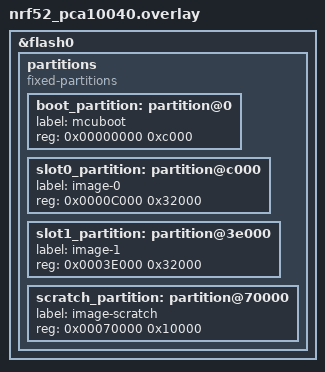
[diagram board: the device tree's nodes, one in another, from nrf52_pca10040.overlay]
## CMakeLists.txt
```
# SPDX-License-Identifier: Apache-2.0

cmake_minimum_required(VERSION 3.28.0)
find_package(Zephyr REQUIRED HINTS $ENV{ZEPHYR_BASE})
project(settings_fcb_raw)

add_subdirectory(./src fcb_test_bindir)

if(TEST)
  target_compile_definitions(app PRIVATE
    -DTEST_${TEST}
  )
endif()
```

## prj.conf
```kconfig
CONFIG_ZTEST=y
CONFIG_ZTEST_STACK_SIZE=2048

CONFIG_FLASH=y
CONFIG_FLASH_MAP=y
CONFIG_FCB=y

CONFIG_SETTINGS=y
CONFIG_SETTINGS_RUNTIME=y
CONFIG_SETTINGS_FCB=y
```

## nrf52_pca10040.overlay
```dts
&flash0 {
	/*
	 * For more information, see:
	 * http://docs.zephyrproject.org/latest/devices/dts/flash_partitions.html
	 */
	partitions {
		compatible = "fixed-partitions";
		#address-cells = <1>;
		#size-cells = <1>;

		boot_partition: partition@0 {
			label = "mcuboot";
			reg = <0x00000000 0xc000>;
		};
		slot0_partition: partition@c000 {
			label = "image-0";
			reg = <0x0000C000 0x32000>;
		};
		slot1_partition: partition@3e000 {
			label = "image-1";
			reg = <0x0003E000 0x32000>;
		};
		scratch_partition: partition@70000 {
			label = "image-scratch";
			reg = <0x00070000 0x10000>;
		};
	};
};
```

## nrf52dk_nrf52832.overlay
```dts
/*
 * Copyright (c) 2018 Nordic Semiconductor ASA
 *
 * SPDX-License-Identifier: Apache-2.0
 */

/delete-node/ &storage_partition;
/delete-node/ &scratch_partition;

&flash0 {

	partitions {
		compatible = "fixed-partitions";
		#address-cells = <1>;
		#size-cells = <1>;

		storage_partition: partition@70000 {
			label = "storage";
			reg = <0x00070000 0x10000>;
		};
	};
};
```

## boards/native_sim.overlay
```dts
/*
 * Copyright (c) 2019 Jan Van Winkel <jan.van_winkel@dxplore.eu>
 *
 * SPDX-License-Identifier: Apache-2.0
 */

/delete-node/ &storage_partition;
/delete-node/ &scratch_partition;

&flash0 {
	partitions {
		compatible = "fixed-partitions";
		#address-cells = <1>;
		#size-cells = <1>;

		storage_partition: partition@70000 {
			reg = <0x00070000 0x10000>;
			label = "storage";
		};
	};
};
```

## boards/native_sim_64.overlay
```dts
/*
 * Copyright (c) 2019 Jan Van Winkel <jan.van_winkel@dxplore.eu>
 *
 * SPDX-License-Identifier: Apache-2.0
 */

#include "native_sim.overlay"
```

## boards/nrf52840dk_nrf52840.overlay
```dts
/*
 * Copyright (c) 2019 Nordic Semiconductor ASA
 *
 * SPDX-License-Identifier: Apache-2.0
 */

/delete-node/ &storage_partition;

&flash0 {
	partitions {
		storage_partition: partition@de000 {
			compatible = "zephyr,mapped-partition";
			reg = <0x000de000 0x00010000>;
			label = "storage";
		};
	};
};
```

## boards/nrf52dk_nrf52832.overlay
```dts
/*
 * Copyright (c) 2018 Nordic Semiconductor ASA
 *
 * SPDX-License-Identifier: Apache-2.0
 */

/delete-node/ &storage_partition;
/delete-node/ &slot1_partition;

&flash0 {
	partitions {
		ranges;
		#address-cells = <1>;
		#size-cells = <1>;

		storage_partition: partition@70000 {
			compatible = "zephyr,mapped-partition";
			label = "storage";
			reg = <0x00070000 0x10000>;
		};
	};
};
```

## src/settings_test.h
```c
/*
 * Copyright (c) 2018 Nordic Semiconductor ASA
 * Copyright (c) 2015 Runtime Inc
 *
 * SPDX-License-Identifier: Apache-2.0
 */

#ifndef _SETTINGS_TEST_FCB_H
#define _SETTINGS_TEST_FCB_H

#include <stdio.h>
#include <string.h>
#include <zephyr/ztest.h>

#include <zephyr/settings/settings.h>
#include <zephyr/storage/flash_map.h>

#ifdef __cplusplus
extern "C" {
#endif

#define SETTINGS_TEST_FCB_VAL_STR_CNT   64
#define SETTINGS_TEST_FCB_FLASH_CNT   4


extern uint8_t val8;
extern uint8_t val8_un;
extern uint32_t val32;
extern uint64_t val64;

extern int test_get_called;
extern int test_set_called;
extern int test_commit_called;
extern int test_export_block;

extern int c2_var_count;

extern const struct flash_sector fcb_sectors[SETTINGS_TEST_FCB_FLASH_CNT];

extern char val_string[SETTINGS_TEST_FCB_VAL_STR_CNT][SETTINGS_MAX_VAL_LEN];
extern char test_ref_value[SETTINGS_TEST_FCB_VAL_STR_CNT][SETTINGS_MAX_VAL_LEN];

extern struct settings_handler c_test_handlers[];

void ctest_clear_call_state(void);
int ctest_get_call_state(void);

void config_wipe_srcs(void);
void config_wipe_fcb(const struct flash_sector *fs, int cnt);

void test_config_fill_area(
	char test_value[SETTINGS_TEST_FCB_VAL_STR_CNT][SETTINGS_MAX_VAL_LEN],
		int iteration);

void *settings_config_setup(void);
void settings_config_teardown(void *fixture);
void test_config_insert2(void);
void test_config_insert3(void);
int settings_unregister(struct settings_handler *handler);
#ifdef __cplusplus
}
#endif
#endif /* _SETTINGS_TEST_FCB_H */
```

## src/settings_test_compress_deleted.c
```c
/*
 * Copyright (c) 2018 Nordic Semiconductor ASA
 *
 * SPDX-License-Identifier: Apache-2.0
 */

#include "settings_test.h"
#include <settings/settings_fcb.h>

#define NAME_DELETABLE "4/deletable"

struct flash_sector fcb_small_sectors[2] = {
	[0] = {
		.fs_off = 0x00000000,
		.fs_size = 4 * 1024
	},
	[1] = {
		.fs_off = 0x00001000,
		.fs_size = 4 * 1024
	}
};

struct deletable_s {
	bool valid;
	uint32_t val32;
} deletable_val;

uint32_t val4v2;

int c4_handle_export(int (*cb)(const char *name, const void *value, size_t val_len));
int c4_handle_set(const char *name, size_t len, settings_read_cb read_cb,
		  void *cb_arg);

struct settings_handler c4_test_handler = {
	.name = "4",
	.h_get = NULL,
	.h_set = c4_handle_set,
	.h_commit = NULL,
	.h_export = c4_handle_export
};

int c4_handle_set(const char *name, size_t len, settings_read_cb read_cb,
		  void *cb_arg)
{
	return 0;
}

int c4_handle_export(int (*cb)(const char *name, const void *value, size_t val_len))
{
	if (deletable_val.valid) {
		(void)cb(NAME_DELETABLE, &deletable_val.val32,
			 sizeof(deletable_val.val32));
	} else {
		(void)cb(NAME_DELETABLE, NULL, 0);
	}

	(void)cb("4/dummy", &val4v2, sizeof(val4v2));

	return 0;
}

static int check_compressed_cb(struct fcb_entry_ctx *entry_ctx, void *arg)
{
	char buf[SETTINGS_MAX_NAME_LEN + SETTINGS_MAX_VAL_LEN +
		 SETTINGS_EXTRA_LEN];
	int rc;
	int len;

	len = entry_ctx->loc.fe_data_len;
	if (len >= sizeof(buf)) {
		len = sizeof(buf) - 1;
	}

	rc = flash_area_read(entry_ctx->fap,
			     FCB_ENTRY_FA_DATA_OFF(entry_ctx->loc), buf, len);

	if (rc) {
		return 0;
	}
	buf[len] = '\0';

	rc = strncmp(buf, NAME_DELETABLE, sizeof(NAME_DELETABLE)-1);
	zassert_true(rc != 0, "The deleted settings shouldn be compressed.");

	return 0;
}

ZTEST(settings_config_fcb, test_config_compress_deleted)
{
	int rc;
	struct settings_fcb cf;
	int i;

	config_wipe_srcs();
	config_wipe_fcb(fcb_small_sectors, ARRAY_SIZE(fcb_small_sectors));

	cf.cf_fcb.f_magic = CONFIG_SETTINGS_FCB_MAGIC;
	cf.cf_fcb.f_sectors = fcb_small_sectors;
	cf.cf_fcb.f_sector_cnt = ARRAY_SIZE(fcb_small_sectors);

	rc = settings_fcb_src(&cf);
	zassert_true(rc == 0, "can't register FCB as configuration source");
	settings_mount_fcb_backend(&cf);

	rc = settings_fcb_dst(&cf);
	zassert_true(rc == 0,
		     "can't register FCB as configuration destination");

	rc = settings_register(&c4_test_handler);
	zassert_true(rc == 0, "settings_register fail");

	deletable_val.valid = true;
	deletable_val.val32 = 2018U;
	val4v2 = 0U;

	rc = settings_save();
	zassert_true(rc == 0, "fcb write error");

	deletable_val.valid = false;

	for (i = 0; ; i++) {
		val4v2++;

		rc = settings_save();
		zassert_true(rc == 0, "fcb write error");

		if (cf.cf_fcb.f_active.fe_sector == &fcb_small_sectors[1]) {
			/*
			 * The compression should happened while the active
			 * sector was changing.
			 */
			break;
		}
	}

	rc = fcb_walk(&cf.cf_fcb, &fcb_small_sectors[1], check_compressed_cb,
		      NULL);
	settings_unregister(&c4_test_handler);
}
```

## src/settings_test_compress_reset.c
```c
/*
 * Copyright (c) 2018 Nordic Semiconductor ASA
 * Copyright (c) 2015 Runtime Inc
 *
 * SPDX-License-Identifier: Apache-2.0
 */

#include "settings_test.h"
#include <settings/settings_fcb.h>

ZTEST(settings_config_fcb, test_config_compress_reset)
{
	int rc;
	struct settings_fcb cf;
	struct flash_sector *fa;
	int elems[4];
	int i;

	rc = settings_register(&c_test_handlers[1]);
	zassert_true(rc == 0 || rc == -EEXIST, "settings_register fail");
	config_wipe_srcs();
	config_wipe_fcb(fcb_sectors, ARRAY_SIZE(fcb_sectors));

	cf.cf_fcb.f_magic = CONFIG_SETTINGS_FCB_MAGIC;
	cf.cf_fcb.f_sectors = fcb_sectors;
	cf.cf_fcb.f_sector_cnt = ARRAY_SIZE(fcb_sectors);

	rc = settings_fcb_src(&cf);
	zassert_true(rc == 0, "can't register FCB as configuration source");
	settings_mount_fcb_backend(&cf);

	rc = settings_fcb_dst(&cf);
	zassert_true(rc == 0,
		     "can't register FCB as configuration destination");

	c2_var_count = 1;
	(void)memset(elems, 0, sizeof(elems));

	for (i = 0; ; i++) {
		test_config_fill_area(test_ref_value, i);
		memcpy(val_string, test_ref_value, sizeof(val_string));

		rc = settings_save();
		zassert_true(rc == 0, "fcb write error");

		if (cf.cf_fcb.f_active.fe_sector == &fcb_sectors[2]) {
			/*
			 * Started using space just before scratch.
			 */
			break;
		}
		(void)memset(val_string, 0, sizeof(val_string));

		rc = settings_load();
		zassert_true(rc == 0, "fcb read error");
		zassert_true(!memcmp(val_string, test_ref_value,
				     SETTINGS_MAX_VAL_LEN),
			     "bad value read");
	}

	fa = cf.cf_fcb.f_active.fe_sector;
	rc = fcb_append_to_scratch(&cf.cf_fcb);
	zassert_true(rc == 0, "fcb_append_to_scratch call failure");
	zassert_true(fcb_free_sector_cnt(&cf.cf_fcb) == 0,
		     "expected non of free sectors");
	zassert_true(fa != cf.cf_fcb.f_active.fe_sector,
		     "active page should change");

	config_wipe_srcs();

	(void)memset(&cf, 0, sizeof(cf));

	cf.cf_fcb.f_magic = CONFIG_SETTINGS_FCB_MAGIC;
	cf.cf_fcb.f_sectors = fcb_sectors;
	cf.cf_fcb.f_sector_cnt = ARRAY_SIZE(fcb_sectors);

	rc = settings_fcb_src(&cf);
	zassert_true(rc == 0, "can't register FCB as configuration source");

	rc = settings_fcb_dst(&cf);
	zassert_true(rc == 0,
		     "can't register FCB as configuration destination");


	zassert_true(fcb_free_sector_cnt(&cf.cf_fcb) == 1,
		     "expected one free sector");
	zassert_true(fa == cf.cf_fcb.f_active.fe_sector,
		   "active sector should become free after garbage collection");

	c2_var_count = 0;
	settings_unregister(&c_test_handlers[1]);
}
```

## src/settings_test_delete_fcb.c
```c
/*
 * Copyright (c) 2019 Nordic Semiconductor ASA
 *
 * SPDX-License-Identifier: Apache-2.0
 */

#include "settings_test.h"
#include <settings/settings_fcb.h>

ZTEST(settings_config_fcb, test_config_delete_fcb)
{
	int rc;
	struct settings_fcb cf;

	rc = settings_register(&c_test_handlers[0]);
	zassert_true(rc == 0 || rc == -EEXIST, "settings_register fail");
	config_wipe_srcs();
	config_wipe_fcb(fcb_sectors, ARRAY_SIZE(fcb_sectors));

	cf.cf_fcb.f_magic = CONFIG_SETTINGS_FCB_MAGIC;
	cf.cf_fcb.f_sectors = fcb_sectors;
	cf.cf_fcb.f_sector_cnt = ARRAY_SIZE(fcb_sectors);

	rc = settings_fcb_src(&cf);
	zassert_true(rc == 0, "can't register FCB as configuration source");

	settings_mount_fcb_backend(&cf);

	rc = settings_fcb_dst(&cf);
	zassert_true(rc == 0,
		     "can't register FCB as configuration destination");

	val8 = 153U;
	rc = settings_save();
	zassert_true(rc == 0, "fcb write error");

	val8 = 0U;

	rc = settings_load();
	zassert_true(rc == 0, "fcb redout error");
	zassert_true(val8 == 153U, "bad value read");

	val8 = 0x55;

	settings_delete("myfoo/mybar");
	rc = settings_load();
	zassert_true(rc == 0, "fcb redout error");
	zassert_true(val8 == 0x55, "bad value read");
	settings_unregister(&c_test_handlers[0]);
}
```

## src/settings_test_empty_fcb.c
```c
/*
 * Copyright (c) 2018 Nordic Semiconductor ASA
 * Copyright (c) 2015 Runtime Inc
 *
 * SPDX-License-Identifier: Apache-2.0
 */

#include "settings_test.h"
#include <settings/settings_fcb.h>

ZTEST(settings_config_fcb, test_config_empty_fcb)
{
	int rc;
	struct settings_fcb cf;

	config_wipe_srcs();
	config_wipe_fcb(fcb_sectors, ARRAY_SIZE(fcb_sectors));

	cf.cf_fcb.f_magic = CONFIG_SETTINGS_FCB_MAGIC;
	cf.cf_fcb.f_sectors = fcb_sectors;
	cf.cf_fcb.f_sector_cnt = ARRAY_SIZE(fcb_sectors);

	rc = settings_fcb_src(&cf);
	zassert_true(rc == 0, "settings_fcb_src call should succeed");

	/*
	 * No values
	 */
	settings_load();

	config_wipe_srcs();
	ctest_clear_call_state();
}
```

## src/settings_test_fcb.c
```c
/*
 * Copyright (c) 2018 Nordic Semiconductor ASA
 * Copyright (c) 2015 Runtime Inc
 *
 * SPDX-License-Identifier: Apache-2.0
 */
#include <stdlib.h>
#include <string.h>

#include "settings_test.h"
#include <settings_priv.h>
#include <zephyr/storage/flash_map.h>

#define TEST_PARTITION		storage_partition
#define TEST_PARTITION_ID	PARTITION_ID(TEST_PARTITION)

uint8_t val8;
uint8_t val8_un;
uint32_t val32;
uint64_t val64;

int test_get_called;
int test_set_called;
int test_commit_called;
int test_export_block;

int c2_var_count = 1;

int c1_handle_get(const char *name, char *val, int val_len_max);
int c1_handle_set(const char *name, size_t len, settings_read_cb read_cb,
		  void *cb_arg);
int c1_handle_commit(void);
int c1_handle_export(int (*cb)(const char *name,
			       const void *value, size_t val_len));

int c2_handle_get(const char *name, char *val, int val_len_max);
int c2_handle_set(const char *name, size_t len, settings_read_cb read_cb,
		  void *cb_arg);
int c2_handle_export(int (*cb)(const char *name,
			       const void *value, size_t val_len));

int c3_handle_get(const char *name, char *val, int val_len_max);
int c3_handle_set(const char *name, size_t len, settings_read_cb read_cb,
		  void *cb_arg);
int c3_handle_export(int (*cb)(const char *name,
			       const void *value, size_t val_len));

struct settings_handler c_test_handlers[] = {
	{
		.name = "myfoo",
		.h_get = c1_handle_get,
		.h_set = c1_handle_set,
		.h_commit = c1_handle_commit,
		.h_export = c1_handle_export
	},
	{
		.name = "2nd",
		.h_get = c2_handle_get,
		.h_set = c2_handle_set,
		.h_commit = NULL,
		.h_export = c2_handle_export
	},
	{
		.name = "3",
		.h_get = c3_handle_get,
		.h_set = c3_handle_set,
		.h_commit = NULL,
		.h_export = c3_handle_export
	}
};

char val_string[SETTINGS_TEST_FCB_VAL_STR_CNT][SETTINGS_MAX_VAL_LEN];
char test_ref_value[SETTINGS_TEST_FCB_VAL_STR_CNT][SETTINGS_MAX_VAL_LEN];

int c1_handle_get(const char *name, char *val, int val_len_max)
{
	const char *next;

	test_get_called = 1;

	if (settings_name_steq(name, "mybar", &next) && !next) {
		val_len_max = MIN(val_len_max, sizeof(val8));
		memcpy(val, &val8, MIN(val_len_max, sizeof(val8)));
		return val_len_max;
	}

	if (settings_name_steq(name, "mybar64", &next) && !next) {
		val_len_max = MIN(val_len_max, sizeof(val64));
		memcpy(val, &val64, MIN(val_len_max, sizeof(val64)));
		return val_len_max;
	}

	return -ENOENT;
}

int c1_handle_set(const char *name, size_t len, settings_read_cb read_cb,
		  void *cb_arg)
{
	size_t val_len;
	int rc;
	const char *next;

	test_set_called = 1;
	if (settings_name_steq(name, "mybar", &next) && !next) {
		rc = read_cb(cb_arg, &val8, sizeof(val8));
		zassert_true(rc >= 0, "SETTINGS_VALUE_SET callback");
		return 0;
	}

	if (settings_name_steq(name, "mybar64", &next) && !next) {
		rc = read_cb(cb_arg, &val64, sizeof(val64));
		zassert_true(rc >= 0, "SETTINGS_VALUE_SET callback");
		return 0;
	}

	if (settings_name_steq(name, "unaligned", &next) && !next) {
		val_len = len;
		zassert_equal(val_len, sizeof(val8_un),
			      "value length: %d, ought equal 1", val_len);
		rc = read_cb(cb_arg, &val8_un, sizeof(val8_un));
		zassert_true(rc >= 0, "SETTINGS_VALUE_SET callback");
		return 0;
	}

	return -ENOENT;
}

int c1_handle_commit(void)
{
	test_commit_called = 1;
	return 0;
}

int c1_handle_export(int (*cb)(const char *name,
			       const void *value, size_t val_len))
{
	if (test_export_block) {
		return 0;
	}

	(void)cb("myfoo/mybar", &val8, sizeof(val8));

	(void)cb("myfoo/mybar64", &val64, sizeof(val64));

	(void)cb("myfoo/unaligned", &val8_un, sizeof(val8_un));

	return 0;
}

void ctest_clear_call_state(void)
{
	test_get_called = 0;
	test_set_called = 0;
	test_commit_called = 0;
}

int ctest_get_call_state(void)
{
	return test_get_called + test_set_called + test_commit_called;
}

void config_wipe_srcs(void)
{
	sys_slist_init(&settings_load_srcs);
	settings_save_dst = NULL;
}

struct flash_sector fcb_sectors[SETTINGS_TEST_FCB_FLASH_CNT] = {
	[0] = {
		.fs_off = 0x00000000,
		.fs_size = 16 * 1024
	},
	[1] = {
		.fs_off = 0x00004000,
		.fs_size = 16 * 1024
	},
	[2] = {
		.fs_off = 0x00008000,
		.fs_size = 16 * 1024
	},
	[3] = {
		.fs_off = 0x0000c000,
		.fs_size = 16 * 1024
	}
};

void config_wipe_fcb(struct flash_sector *fs, int cnt)
{
	const struct flash_area *fap;
	int rc;
	int i;

	rc = flash_area_open(TEST_PARTITION_ID, &fap);

	for (i = 0; i < cnt; i++) {
		rc = flash_area_flatten(fap, fs[i].fs_off, fs[i].fs_size);
		zassert_true(rc == 0, "Can't get flash area");
	}
}

void
test_config_fill_area(char test_value[SETTINGS_TEST_FCB_VAL_STR_CNT]
				     [SETTINGS_MAX_VAL_LEN],
		      int iteration)
{
	int i, j;

	for (j = 0; j < 64; j++) {
		for (i = 0; i < SETTINGS_MAX_VAL_LEN; i++) {
			test_value[j][i] = ((j * 2) + i + iteration) % 10 + '0';
		}
		test_value[j][sizeof(test_value[j]) - 1] = '\0';
	}
}

char *c2_var_find(char *name)
{
	int idx = 0;
	int len;
	char *eptr;

	len = strlen(name);
	zassert_true(len > 6, "string type expected");
	zassert_true(!strncmp(name, "string", 6), "string type expected");

	idx = strtoul(&name[6], &eptr, 10);
	zassert_true(*eptr == '\0', "EOF");
	zassert_true(idx < c2_var_count,
		     "var index greater than any exporter");

	return val_string[idx];
}

int c2_handle_get(const char *name, char *val, int val_len_max)
{
	int len;
	char *valptr;
	const char *next;
	char argv[32];

	len = settings_name_next(name, &next);
	if (len && !next) {
		strncpy(argv, name, len);
		argv[len] = '\0';
		valptr = c2_var_find(argv);
		if (!valptr) {
			return -ENOENT;
		}

		len = strlen(val_string[0]);
		if (len > val_len_max) {
			len = val_len_max;
		}

		len = MIN(strlen(valptr), len);
		memcpy(val, valptr, len);
		return len;
	}

	return -ENOENT;
}

int c2_handle_set(const char *name, size_t len, settings_read_cb read_cb,
		  void *cb_arg)
{
	char *valptr;
	const char *next;
	char argv[32];

	int rc;

	len = settings_name_next(name, &next);
	if (len && !next) {
		strncpy(argv, name, len);
		argv[len] = '\0';
		valptr = c2_var_find(argv);
		if (!valptr) {
			return -ENOENT;
		}

		rc = read_cb(cb_arg, valptr, sizeof(val_string[0]));
		zassert_true(rc >= 0, "SETTINGS_VALUE_SET callback");
		if (rc == 0) {
			(void)memset(valptr, 0, sizeof(val_string[0]));
		}

		return 0;
	}

	return -ENOENT;
}

int c2_handle_export(int (*cb)(const char *name,
			       const void *value, size_t val_len))
{
	int i;
	char name[32];

	for (i = 0; i < c2_var_count; i++) {
		snprintf(name, sizeof(name), "2nd/string%d", i);
		(void)cb(name, val_string[i], strlen(val_string[i]));
	}

	return 0;
}

int c3_handle_get(const char *name, char *val, int val_len_max)
{
	const char *next;

	if (settings_name_steq(name, "v", &next) && !next) {
		val_len_max = MIN(val_len_max, sizeof(val32));
		memcpy(val, &val32, MIN(val_len_max, sizeof(val32)));
		return val_len_max;
	}
	return -EINVAL;
}

int c3_handle_set(const char *name, size_t len, settings_read_cb read_cb,
		  void *cb_arg)
{
	int rc;
	size_t val_len;
	const char *next;

	if (settings_name_steq(name, "v", &next) && !next) {
		val_len = len;
		zassert_true(val_len == 4, "bad set-value size");

		rc = read_cb(cb_arg, &val32, sizeof(val32));
		zassert_true(rc >= 0, "SETTINGS_VALUE_SET callback");
		return 0;
	}

	return -ENOENT;
}

int c3_handle_export(int (*cb)(const char *name,
			       const void *value, size_t val_len))
{
	(void)cb("3/v", &val32, sizeof(val32));


	return 0;
}

void *settings_config_fcb_setup(void)
{
	const struct flash_area *fap;
	int rc;
	uint8_t wbs;

	rc = flash_area_open(TEST_PARTITION_ID, &fap);
	zassume_true(rc == 0, "Can't open storage flash area");

	wbs = flash_area_align(fap);
	zassume_true(wbs <= 32,
		"Flash driver is not compatible with the settings fcb-backend");
	return NULL;
}

ZTEST(settings_config_fcb, test_config_insert_handler2)
{
	test_config_insert2();
}

ZTEST(settings_config_fcb, test_config_insert_handler3)
{
	test_config_insert3();
}

ZTEST_SUITE(settings_config, NULL, settings_config_setup, NULL, NULL,
	    settings_config_teardown);
ZTEST_SUITE(settings_config_fcb, NULL, settings_config_fcb_setup,
	    NULL, NULL, NULL);
```

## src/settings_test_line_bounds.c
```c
/*
 * SPDX-FileCopyrightText: Copyright The Zephyr Project Contributors
 * SPDX-License-Identifier: Apache-2.0
 */

#include <string.h>

#include <zephyr/ztest.h>
#include <settings_priv.h>

#define FAKE_RWBS 16U
#define FAKE_SHORT_READ_LEN 4U

static uint8_t line_bounds_fake_store[64];

static int line_bounds_fake_read_cb_short(void *ctx, off_t off, char *buf, size_t *len)
{
	ARG_UNUSED(ctx);
	ARG_UNUSED(off);

	*len = MIN(*len, FAKE_SHORT_READ_LEN);
	memset(buf, 0xAA, *len);

	return 0;
}

static int line_bounds_fake_read_cb_full(void *ctx, off_t off, char *buf, size_t *len)
{
	ARG_UNUSED(ctx);

	size_t avail = sizeof(line_bounds_fake_store) - MIN(sizeof(line_bounds_fake_store),
							     (size_t)off);

	*len = MIN(*len, avail);
	memcpy(buf, &line_bounds_fake_store[off], *len);

	return 0;
}

static size_t line_bounds_fake_get_len_cb(void *ctx)
{
	ARG_UNUSED(ctx);

	return 4;
}

static void *settings_line_bounds_setup(void)
{
	for (size_t i = 0; i < sizeof(line_bounds_fake_store); i++) {
		line_bounds_fake_store[i] = (uint8_t)i;
	}

	return NULL;
}

ZTEST(settings_line_bounds, test_val_get_len_returns_zero_past_end)
{
	size_t len;

	settings_line_io_init(line_bounds_fake_read_cb_short, NULL, line_bounds_fake_get_len_cb,
			       FAKE_RWBS);

	len = settings_line_val_get_len(10, NULL);

	zassert_equal(len, 0, "expected 0 for val_off past the record end, got %zu", len);
}

ZTEST(settings_line_bounds, test_raw_read_short_backend_no_overflow)
{
	char out[40];
	size_t len_read = 123;
	int rc;

	settings_line_io_init(line_bounds_fake_read_cb_short, NULL, line_bounds_fake_get_len_cb,
			       FAKE_RWBS);

	rc = settings_line_raw_read(10, out, sizeof(out), &len_read, NULL);

	zassert_equal(rc, 0, "unexpected error %d", rc);
	zassert_equal(len_read, 0, "expected no bytes read past the end of backend data, got %zu",
		      len_read);
}

ZTEST(settings_line_bounds, test_raw_read_normal_still_works)
{
	char out[10];
	size_t len_read = 0;
	int rc;

	settings_line_io_init(line_bounds_fake_read_cb_full, NULL, line_bounds_fake_get_len_cb,
			       FAKE_RWBS);

	rc = settings_line_raw_read(5, out, sizeof(out), &len_read, NULL);

	zassert_equal(rc, 0, "unexpected error %d", rc);
	zassert_equal(len_read, sizeof(out), "short read, got %zu", len_read);
	zassert_mem_equal(out, &line_bounds_fake_store[5], sizeof(out));
}

ZTEST_SUITE(settings_line_bounds, NULL, settings_line_bounds_setup, NULL, NULL, NULL);
```

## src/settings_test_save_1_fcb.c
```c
/*
 * Copyright (c) 2018 Nordic Semiconductor ASA
 * Copyright (c) 2015 Runtime Inc
 *
 * SPDX-License-Identifier: Apache-2.0
 */

#include "settings_test.h"
#include <settings/settings_fcb.h>

ZTEST(settings_config_fcb, test_config_save_1_fcb)
{
	int rc;
	struct settings_fcb cf;

	rc = settings_register(&c_test_handlers[0]);
	zassert_true(rc == 0 || rc == -EEXIST, "settings_register fail");

	config_wipe_srcs();
	config_wipe_fcb(fcb_sectors, ARRAY_SIZE(fcb_sectors));

	cf.cf_fcb.f_magic = CONFIG_SETTINGS_FCB_MAGIC;
	cf.cf_fcb.f_sectors = fcb_sectors;
	cf.cf_fcb.f_sector_cnt = ARRAY_SIZE(fcb_sectors);

	rc = settings_fcb_src(&cf);
	zassert_true(rc == 0, "can't register FCB as configuration source");

	settings_mount_fcb_backend(&cf);

	rc = settings_fcb_dst(&cf);
	zassert_true(rc == 0,
		     "can't register FCB as configuration destination");

	val8 = 33U;
	rc = settings_save();
	zassert_true(rc == 0, "fcb write error");

	val8 = 0U;

	rc = settings_load();
	zassert_true(rc == 0, "fcb redout error");
	zassert_true(val8 == 33U, "bad value read");

	val8 = 15U;
	rc = settings_save();
	zassert_true(rc == 0, "fcb write error");
	settings_unregister(&c_test_handlers[0]);
}
```

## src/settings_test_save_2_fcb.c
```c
/*
 * Copyright (c) 2018 Nordic Semiconductor ASA
 * Copyright (c) 2015 Runtime Inc
 *
 * SPDX-License-Identifier: Apache-2.0
 */

#include "settings_test.h"
#include <settings/settings_fcb.h>

#ifdef TEST_LONG
#define TESTS_S2_FCB_ITERATIONS 32
#else
#define TESTS_S2_FCB_ITERATIONS 2
#endif

ZTEST(settings_config_fcb, test_config_save_2_fcb)
{
	int rc;
	struct settings_fcb cf;

	int i;

	/* this case need c_test_handler[0] to handle access to val8 */
	rc = settings_register(&c_test_handlers[0]);
	zassert_true(rc == 0 || rc == -EEXIST, "settings_register fail");
	rc = settings_register(&c_test_handlers[1]);
	zassert_true(rc == 0 || rc == -EEXIST, "settings_register fail");

	config_wipe_srcs();

	cf.cf_fcb.f_magic = CONFIG_SETTINGS_FCB_MAGIC;
	cf.cf_fcb.f_sectors = fcb_sectors;
	cf.cf_fcb.f_sector_cnt = ARRAY_SIZE(fcb_sectors);

	rc = settings_fcb_src(&cf);
	zassert_true(rc == 0, "can't register FCB as configuration source");
	settings_mount_fcb_backend(&cf);

	rc = settings_fcb_dst(&cf);
	zassert_true(rc == 0,
		     "can't register FCB as configuration destination");

	test_config_fill_area(test_ref_value, 0);
	memcpy(val_string, test_ref_value, sizeof(val_string));

	c2_var_count = 1;
	printk("save val8 and val_string\n");
	val8 = 42U;
	rc = settings_save();
	zassert_true(rc == 0, "fcb write error");

	printk("load val8 and val_string\n");
	val8 = 0U;
	(void)memset(val_string[0], 0, sizeof(val_string[0]));
	rc = settings_load();
	zassert_true(rc == 0, "fcb read error");
	zassert_true(val8 == 42U, "bad value read");
	zassert_str_equal(val_string[0], test_ref_value[0], "bad value read");
	test_export_block = 1;

	/*
	 * Now add the number of settings to max. Keep adjusting the test_data,
	 * check that rollover happens when it's supposed to.
	 */
	c2_var_count = 64;

	for (i = 0; i < TESTS_S2_FCB_ITERATIONS; i++) {
		test_config_fill_area(test_ref_value, i);
		memcpy(val_string, test_ref_value, sizeof(val_string));

		rc = settings_save();
		zassert_true(rc == 0, "fcb write error");

		(void)memset(val_string, 0, sizeof(val_string));

		val8 = 0U;
		rc = settings_load();
		zassert_true(rc == 0, "fcb read error");
		zassert_true(!memcmp(val_string, test_ref_value,
				     sizeof(val_string)),
			     "bad value read");
		zassert_true(val8 == 42U, "bad value read");
	}
	c2_var_count = 0;
	test_export_block = 0;
	settings_unregister(&c_test_handlers[1]);
	settings_unregister(&c_test_handlers[0]);
}
```

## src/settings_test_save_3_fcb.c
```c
/*
 * Copyright (c) 2018 Nordic Semiconductor ASA
 * Copyright (c) 2015 Runtime Inc
 *
 * SPDX-License-Identifier: Apache-2.0
 */

#include "settings_test.h"
#include <settings/settings_fcb.h>

#ifdef TEST_LONG
#define TESTS_S3_FCB_ITERATIONS 4096
#else
#define TESTS_S3_FCB_ITERATIONS 100
#endif

ZTEST(settings_config_fcb, test_config_save_3_fcb)
{
	int rc;
	struct settings_fcb cf;
	int i;

	rc = settings_register(&c_test_handlers[2]);
	zassert_true(rc == 0 || rc == -EEXIST, "settings_register fail");
	config_wipe_srcs();
	config_wipe_fcb(fcb_sectors, ARRAY_SIZE(fcb_sectors));

	cf.cf_fcb.f_magic = CONFIG_SETTINGS_FCB_MAGIC;
	cf.cf_fcb.f_sectors = fcb_sectors;
	cf.cf_fcb.f_sector_cnt = 4;

	rc = settings_fcb_src(&cf);
	zassert_true(rc == 0, "can't register FCB as configuration source");

	rc = settings_fcb_dst(&cf);
	zassert_true(rc == 0,
		     "can't register FCB as configuration destination");

	for (i = 0; i < TESTS_S3_FCB_ITERATIONS; i++) {
		val32 = i;

		rc = settings_save();
		zassert_true(rc == 0, "fcb write error");

		val32 = 0U;

		rc = settings_load();
		zassert_true(rc == 0, "fcb read error");
		zassert_true(val32 == i, "bad value read");
	}
	settings_unregister(&c_test_handlers[2]);
}
```

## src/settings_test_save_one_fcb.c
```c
/*
 * Copyright (c) 2018 Nordic Semiconductor ASA
 * Copyright (c) 2015 Runtime Inc
 *
 * SPDX-License-Identifier: Apache-2.0
 */

#include "settings_test.h"
#include <settings/settings_fcb.h>

static int test_config_save_one_byte_value(const char *name, uint8_t val)
{
	return settings_save_one(name, &val, 1);
}

ZTEST(settings_config_fcb, test_config_save_one_fcb)
{
	int rc;
	struct settings_fcb cf;

	rc = settings_register(&c_test_handlers[0]);
	zassert_true(rc == 0 || rc == -EEXIST, "settings_register fail");
	config_wipe_srcs();
	config_wipe_fcb(fcb_sectors, ARRAY_SIZE(fcb_sectors));

	cf.cf_fcb.f_magic = CONFIG_SETTINGS_FCB_MAGIC;
	cf.cf_fcb.f_sectors = fcb_sectors;
	cf.cf_fcb.f_sector_cnt = ARRAY_SIZE(fcb_sectors);

	rc = settings_fcb_src(&cf);
	zassert_true(rc == 0, "can't register FCB as configuration source");
	settings_mount_fcb_backend(&cf);

	rc = settings_fcb_dst(&cf);
	zassert_true(rc == 0,
			 "can't register FCB as configuration destination");

	val8 = 33U;
	rc = settings_save();
	zassert_true(rc == 0, "fcb write error");

	rc = test_config_save_one_byte_value("myfoo/mybar", 42);
	zassert_true(rc == 0, "fcb one item write error");

	rc = settings_load();
	zassert_true(rc == 0, "fcb read error");
	zassert_true(val8 == 42U, "bad value read");

	rc = test_config_save_one_byte_value("myfoo/mybar", 44);
	zassert_true(rc == 0, "fcb one item write error");

	rc = settings_load();
	zassert_true(rc == 0, "fcb read error");
	zassert_true(val8 == 44U, "bad value read");
	settings_unregister(&c_test_handlers[0]);
}
```

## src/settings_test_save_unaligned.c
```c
/*
 * Copyright (c) 2019 Nordic Semiconductor ASA
 *
 * SPDX-License-Identifier: Apache-2.0
 */

#include "settings_test.h"
#include <settings/settings_fcb.h>

ZTEST(settings_config_fcb, test_config_save_fcb_unaligned)
{
	int rc;
	struct settings_fcb cf;

	rc = settings_register(&c_test_handlers[0]);
	zassert_true(rc == 0 || rc == -EEXIST, "settings_register fail");

	config_wipe_srcs();
	config_wipe_fcb(fcb_sectors, ARRAY_SIZE(fcb_sectors));

	cf.cf_fcb.f_magic = CONFIG_SETTINGS_FCB_MAGIC;
	cf.cf_fcb.f_sectors = fcb_sectors;
	cf.cf_fcb.f_sector_cnt = ARRAY_SIZE(fcb_sectors);

	rc = settings_fcb_src(&cf);
	zassert_true(rc == 0, "can't register FCB as configuration source");

	if (cf.cf_fcb.f_align == 1) {
		/* override flash driver alignment */
		cf.cf_fcb.f_align = 4;
	}

	settings_mount_fcb_backend(&cf);

	rc = settings_fcb_dst(&cf);
	zassert_true(rc == 0,
		     "can't register FCB as configuration destination");

	val8_un = 33U;
	rc = settings_save();
	zassert_true(rc == 0, "fcb write error");

	val8_un = 0U;

	rc = settings_load();
	zassert_true(rc == 0, "fcb redout error");
	zassert_true(val8_un == 33U, "bad value read");

	val8_un = 15U;
	rc = settings_save();
	zassert_true(rc == 0, "fcb write error");
	settings_unregister(&c_test_handlers[0]);
}
```
